# SEC_MMR0_BOOT_CTRL register map
Vendor: Texas Instruments
Peripheral module from a debugger description file (folder J7_AHP).
Registers are 32-bit, read-write, reset 0x0 unless marked. A register's access mark holds for its fields unless they carry their own. Offsets are as the file gives them; lines under a group give offsets from that group; [hi:lo] are bit positions; {n}, {i} and the like mark numbered series; 'fields as' and 'values as' point back to an identical list; <NAME> marks a mode.

## SEC_MMR0_BOOT_CTRL
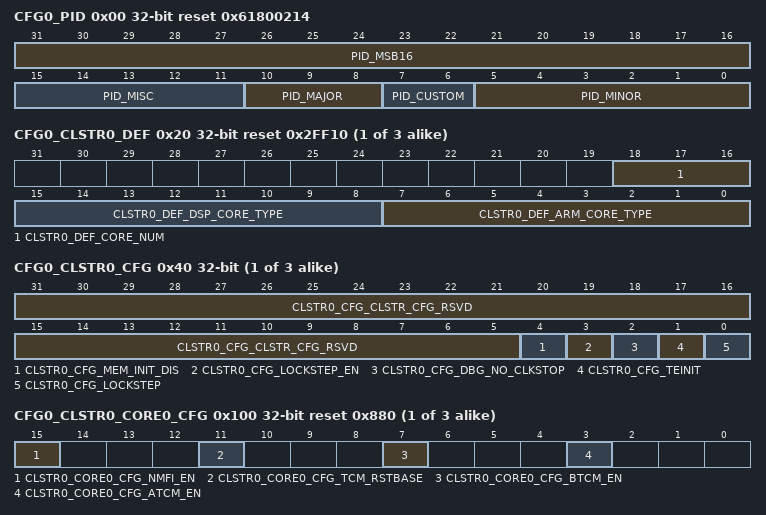
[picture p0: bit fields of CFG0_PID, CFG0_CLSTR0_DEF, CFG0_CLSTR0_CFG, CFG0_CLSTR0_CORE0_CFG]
0x00 CFG0_PID ro reset 0x61800214
  [31:16] PID_MSB16, [15:11] PID_MISC, [10:8] PID_MAJOR, [7:6] PID_CUSTOM, [5:0] PID_MINOR
{0x20+0x1000*i} CFG0_CLSTR{i}_DEF ro reset 0x2FF10 (i=0..2) — Defines the type of the processor cluster
  [18:16] CLSTR{i}_DEF_CORE_NUM — Number of cores in cluster 001 - Single Core 010 - Dual Core 100 - Quad Core
  [15:8] CLSTR{i}_DEF_DSP_CORE_TYPE — DSP core type configuration Field values (Others are reserved): 8'h00 - C7x 8'h01 - C6x 8'hFF - Not DSP
  [7:0] CLSTR{i}_DEF_ARM_CORE_TYPE — ARM core type configuration Field values (Others are reserved): 8'h00 - A53 8'h01 - A57 8'h10 - R5 8'hFF - Not ARM
{0x40+0x1000*i} CFG0_CLSTR{i}_CFG access per field (i=0..2) — Configures cluster level characteristics
  [31:5] CLSTR{i}_CFG_CLSTR_CFG_RSVD rw — Reserved for future use. Write '0' to ensure compatibility with future devices.
  [4] CLSTR{i}_CFG_MEM_INIT_DIS rw — Disables SRAM initialization (TCM, Cache Tags, etc) at resetInitialization must be performed for proper initial ECC initialization. The mem_init_dis value must be selected prior to R5 reset assertion. 1'b0 - Perform memory initialization 1'b1 - Disable memory initialization
  [3] CLSTR{i}_CFG_LOCKSTEP_EN ro — Lockstep enable. Indicates if R5 lockstep operation is supported on the device
  [2] CLSTR{i}_CFG_DBG_NO_CLKSTOP rw — CPU clockstop behavior 0 - CPU clocks stopped and nCLOCKSTOPPED asserted in standby mode 1 - CPU clocks not stopped in standby mode
  [1] CLSTR{i}_CFG_TEINIT rw — Exception handling state at reset:0 - ARM mode1 - Thumb mode
  [0] CLSTR{i}_CFG_LOCKSTEP rw — When set, Core0 and Core1 operate in lockstep mode. Can only be changed if lockstep operation is supported as indicated by CLSTR{i}_CFG_lockstep_en = 1. If CLSTR{i}_CFG_lockstep_en = 0, lockstep is not supported, this bit will be read only with a value of 0.
{0x80+0x1000*i} CFG0_CLSTR{i}_PMCTRL access not given (i=0..2) — Configures Cluster overall power state
{0x90+0x1000*i} CFG0_CLSTR{i}_PMSTAT access not given (i=0..2) — Shows Cluster overall power status
{0x100+0x1000*i} CFG0_CLSTR{i}_CORE0_CFG reset 0x880 (i=0..2) — Configures the TCM and interrupt operation of R5 Core0
  [15] CLSTR{i}_CORE0_CFG_NMFI_EN — Enable Core0 Non-Maskable Fast Interrupts
  [11] CLSTR{i}_CORE0_CFG_TCM_RSTBASE — Core0 A/BTCM Reset Base Address Indicator 0 - BTCM located at address 0x0 1 - ATCM located at address 0x0
  [7] CLSTR{i}_CORE0_CFG_BTCM_EN — Enable Core0 BTCM RAM at reset
  [3] CLSTR{i}_CORE0_CFG_ATCM_EN — Enable Core0 ATCM RAM at reset
{0x110+0x1000*i} CFG0_CLSTR{i}_CORE0_BOOTVECT_LO reset 0x200 (i=0..2) — Contains the lower 32 bits of the boot vector location for R5 Core0. Bits 4:0 are not used and are always 0.
  [31:7] CLSTR{i}_CORE0_BOOTVECT_LO_VECT_ADDR — Specifies the lower 25 bits of the 41-bit vector address corresponding to Vector Table address bits[31:7]. Note bits 6:0 of the Vector Table address are always 0.
{0x114+0x1000*i} CFG0_CLSTR{i}_CORE0_BOOTVECT_HI (i=0..2) — Contains the lower 16 bits of the boot vector location for R5 Core0
  [15:0] CLSTR{i}_CORE0_BOOTVECT_HI_VECT_ADDR — Specifies the upper 16 bits of the 41-bit vector address corresponding to Vector Table address bits[47:32].
{0x120+0x1000*i} CFG0_CLSTR{i}_CORE0_PMCTRL (i=0..2) — Configures Cluster Core0 power state
  [0] CLSTR{i}_CORE0_PMCTRL_CORE_HALT — Halt Core0
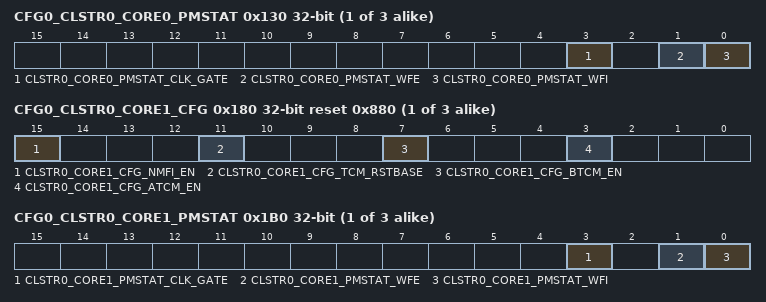
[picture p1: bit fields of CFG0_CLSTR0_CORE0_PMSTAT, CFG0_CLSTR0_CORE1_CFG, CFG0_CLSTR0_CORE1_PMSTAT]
{0x130+0x1000*i} CFG0_CLSTR{i}_CORE0_PMSTAT ro (i=0..2) — Shows Cluster Core0 power status
  [3] CLSTR{i}_CORE0_PMSTAT_CLK_GATE — Core0 Clocked stopped due to WFI or WFE state
  [1] CLSTR{i}_CORE0_PMSTAT_WFE — Core0 WFEWhen 0, indicates that Core0 is in the WFE state
  [0] CLSTR{i}_CORE0_PMSTAT_WFI — Core0 WFIWhen 0, indicates that Core0 is in the WFI state
{0x180+0x1000*i} CFG0_CLSTR{i}_CORE1_CFG reset 0x880 (i=0..2) — Configures the TCM and interrupt operation of R5 Core1
  [15] CLSTR{i}_CORE1_CFG_NMFI_EN — Enable Core1 Non-Maskable Fast Interrupts
  [11] CLSTR{i}_CORE1_CFG_TCM_RSTBASE — Core1 A/BTCM Reset Base Address Indicator 0 - BTCM located at address 0x0 1 - ATCM located at address 0x0
  [7] CLSTR{i}_CORE1_CFG_BTCM_EN — Enable Core1 BTCM RAM at reset
  [3] CLSTR{i}_CORE1_CFG_ATCM_EN — Enable Core1 ATCM RAM at reset
{0x190+0x1000*i} CFG0_CLSTR{i}_CORE1_BOOTVECT_LO reset 0x200 (i=0..2) — Contains the lower 32 bits of the boot vector location for R5 Core1. Bits 4:0 are not used and are always 0.
  [31:7] CLSTR{i}_CORE1_BOOTVECT_LO_VECT_ADDR — Specifies the lower 25 bits of the 41-bit vector address corresponding to Vector Table address bits[31:7]. Note bits 6:0 of the Vector Table address are always 0.
{0x194+0x1000*i} CFG0_CLSTR{i}_CORE1_BOOTVECT_HI (i=0..2) — Contains the lower 16 bits of the boot vector location for R5 Core1
  [15:0] CLSTR{i}_CORE1_BOOTVECT_HI_VECT_ADDR — Specifies the upper 16 bits of the 41-bit vector address corresponding to Vector Table address bits[47:32].
{0x1A0+0x1000*i} CFG0_CLSTR{i}_CORE1_PMCTRL (i=0..2) — Configures Cluster Core1 power state
  [0] CLSTR{i}_CORE1_PMCTRL_CORE_HALT — Halt Core1
{0x1B0+0x1000*i} CFG0_CLSTR{i}_CORE1_PMSTAT ro (i=0..2) — Shows Cluster Core1 power status
  [3] CLSTR{i}_CORE1_PMSTAT_CLK_GATE — Core1 Clocked stopped due to WFI or WFE state
  [1] CLSTR{i}_CORE1_PMSTAT_WFE — Core1 WFEWhen 0, indicates that Core1 is in the WFE state
  [0] CLSTR{i}_CORE1_PMSTAT_WFI — Core1 WFIWhen 0, indicates that Core1 is in the WFI state
